# PIC32CK1012SG00048 device description
Architecture: CORTEX-M33; Family: PIC32CK; Series: PIC32CKSG00
Registers are 32-bit, read-write, reset 0x0 unless marked. A register's access mark holds for its fields unless they carry their own. Offsets are from the block's base; [hi:lo] are bit positions; {n}, {i} and the like mark numbered series; <NAME> marks a mode.

## FREQM — Frequency Meter
Instances: FREQM 0x44014000
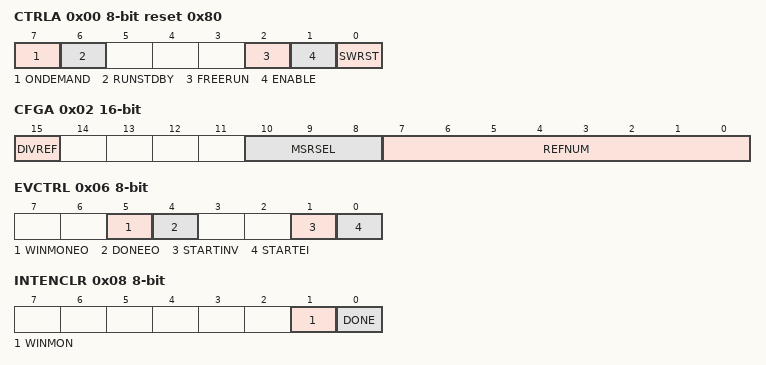
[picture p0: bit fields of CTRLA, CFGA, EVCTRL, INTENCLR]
0x00 CTRLA 8-bit reset 0x80 — Control A Register
  [7] ONDEMAND — On Demand Control
  [6] RUNSTDBY — Run In Standby
  [2] FREERUN — Free Running Mode
  [1] ENABLE
  [0] SWRST — Software Reset
0x01 CTRLB 8-bit wo — Control B Register
  [0] START — Start Measurement
0x02 CFGA 16-bit — Config A Register
  [15] DIVREF — Divide Reference Clock
    0=DIV1 (The reference clock is divided by 1); 1=DIV8 (The reference clock is divided by 8)
  [10:8] MSRSEL — Measurement Clock Selection
    0=GCLK (GCLK Input Clock); 1=CPU (CPU Input Clock)
  [7:0] REFNUM — Number of Reference Clock Cycles
0x04 CTRLC 8-bit — Control C Register
  [2:0] WINMODE — Window Monitor Mode
    0=DISABLE (No window mode (default)); 1=MODE1 (VALUE > WINLT); 2=MODE2 (VALUE < WINUT); 3=MODE3 (WINLT < VALUE < WINUT); 4=MODE4 (!(WINLT < VALUE < WINUT))
0x06 EVCTRL 8-bit — Event Control Register
  [5] WINMONEO — Window Monitor Event Out
  [4] DONEEO — Measurement Done Event Out
  [1] STARTINV — Start Measurement Event Invert Enable
  [0] STARTEI — Start Measurement Event Input Enable
0x08 INTENCLR 8-bit (atomic clear) — Interrupt Enable Clear Register
  [1] WINMON — Window Monitor Interrupt Disable
  [0] DONE — Measurement Done Interrupt Disable
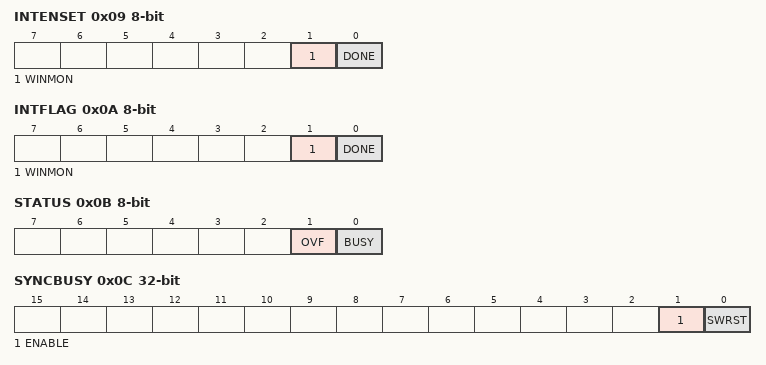
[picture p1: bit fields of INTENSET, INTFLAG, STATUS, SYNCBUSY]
0x09 INTENSET 8-bit (atomic set) — Interrupt Enable Set Register
  [1] WINMON — Window Monitor Interrupt Enable
  [0] DONE — Measurement Done Interrupt Enable
0x0A INTFLAG 8-bit (atomic clear) — Interrupt Flag Register
  [1] WINMON — Window Monitor
  [0] DONE — Measurement Done
0x0B STATUS 8-bit
  [1] OVF — Sticky Count Value Overflow
  [0] BUSY — FREQM Status
0x0C SYNCBUSY ro — Synchronization Busy Register
  [1] ENABLE
  [0] SWRST — Software Reset
0x10 VALUE ro — Count Value Register
  [23:0] VALUE — Measurement Value
0x20 WINLT — Window Monitor Lower Threshold
  [23:0] WINLT — Window Lower Threshold
0x24 WINUT — Window Monitor Upper Threshold
  [23:0] WINUT — Window Upper Threshold

## FUSES_BOOTCFG1 — Defines FUSE parameters
Instances: FUSES_BOOTCFG1 0x0A002000, FUSES_BOOTCFG2 0x0A00A000
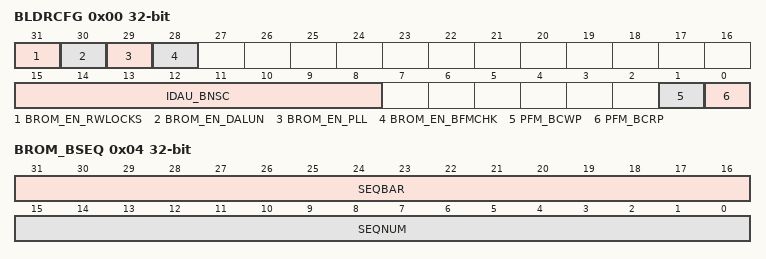
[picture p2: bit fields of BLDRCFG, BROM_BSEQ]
0x00 BLDRCFG reset not defined — Bootloader Configuration
  [31] BROM_EN_RWLOCKS — Enable Read/Write Locks
  [30] BROM_EN_DALUN — Enable DAL Unlock
  [29] BROM_EN_PLL — Enable PLL (Settings in PLL0_<REGS> are used)
  [28] BROM_EN_BFMCHK — Enable BFM CRC Check
    0=NONE (No verification); 1=CRC32 (Verify using crc32)
  [15:8] IDAU_BNSC — Boot Non-Secure Callable Size
  [1] PFM_BCWP — Boot Configration Page Write Protect
  [0] PFM_BCRP — Boot Configration Page Read Protect
0x04 BROM_BSEQ reset not defined — Boot Configuraiton Page Sequence Number
  [31:16] SEQBAR — Sequence Number Bar (Negeated)
  [15:0] SEQNUM — Sequence Number
0x08 BFM_CHK_TABLEPTR reset not defined — BFM CRC Table Pointer
{0x20+4i} KEYVAL_TZ1_CE_NS[{i}] (i=0..3) reset not defined — Chip Erase Key for TZ1_NS
{0x30+4i} CELOCK_TZ1_CE_NS[{i}] (i=0..3) reset not defined — Chip Erase Lock for TZ1_NS
{0x40+4i} KEYVAL_TZ1_CE_S[{i}] (i=0..3) reset not defined — Chip Erase Key for TZ1_S
{0x50+4i} CELOCK_TZ1_CE_S[{i}] (i=0..3) reset not defined — Chip Erase Lock for TZ1_S
{0x60+4i} KEYVAL_TZ1_CE_ALL[{i}] (i=0..3) reset not defined — Chip Erase Key for TZ1_ALL
{0x70+4i} CELOCK_TZ1_CE_ALL[{i}] (i=0..3) reset not defined — Chip Erase Lock for TZ1_ALL
{0x80+4i} KEYVAL_TZ0_CE_ALL[{i}] (i=0..3) reset not defined — Chip Erase Key for TZ0_ALL
{0x90+4i} CELOCK_TZ0_CE_ALL[{i}] (i=0..3) reset not defined — Chip Erase Lock for TZ0_ALL
{0xA0+4i} KEYVAL_CRCCMD[{i}] (i=0..3) reset not defined — CRC Access Key
{0xB0+4i} KEYCONFIG_CRCCMD[{i}] (i=0..3) reset not defined — CRC Access Key Configuration
{0xC0+4i} KEYVAL_HOSTDALELEV[{i}] (i=0..3) reset not defined — Host Authenticated DAL Elevation Key
{0xD0+4i} KEYCONFIG_HOSTDALELEV[{i}] (i=0..3) reset not defined — Host Authenticated DAL Elevation Key Configuration
0xE0 ROM_CTRLA reset not defined — ROM CTRLA Settings (BROM_PLLEN must be set)
0xE4 FCR_CTRLA reset not defined — FCR CTRLA Settings (BROM_PLLEN must be set)
0xE8 RPMU_VREGCTRL reset not defined — RPMU VREGCTRL Settings (BROM_PLLEN must be set)
0xEC PLL0_CTRL reset not defined — PLL0 CTRL Settings (BROM_PLLEN must be set)
0xF0 PLL0_FBDIV reset not defined — PLL0 FBDIV Settings (BROM_PLLEN must be set)
0xF4 PLL0_REFDIV reset not defined — PLL0 REFDIV Settings (BROM_PLLEN must be set)
0xF8 PLL0_POSTDIVA reset not defined — PLL0 POSTDIVA Settings (BROM_PLLEN must be set)
0xFC MCLK_CLKDIV1 reset not defined — MCLK CLKDIV1 Settings (BROM_PLLEN must be set)
0x100 GCLK_GENCTRL0 reset not defined — GCLK GENCTRL0 Settings (BROM_PLLEN must be set)
{0x110+4i} BROM_BOOTCFGCRC[{i}] (i=0..3) reset not defined — Boot Configuraiton Page CRC
0x120 BROM_PAGEEND reset not defined — Page End Marker for Verified Data

## Notices in the file
Copyright (c) 2021 Microchip Technology Inc.
SPDX-License-Identifier: Apache-2.0
Licensed under the Apache License, Version 2.0 (the "License");
you may not use this file except in compliance with the License.
You may obtain a copy of the License at
http://www.apache.org/licenses/LICENSE-2.0
Unless required by applicable law or agreed to in writing, software
distributed under the License is distributed on an "AS IS" BASIS,
WITHOUT WARRANTIES OR CONDITIONS OF ANY KIND, either express or implied.
See the License for the specific language governing permissions and
limitations under the License.
